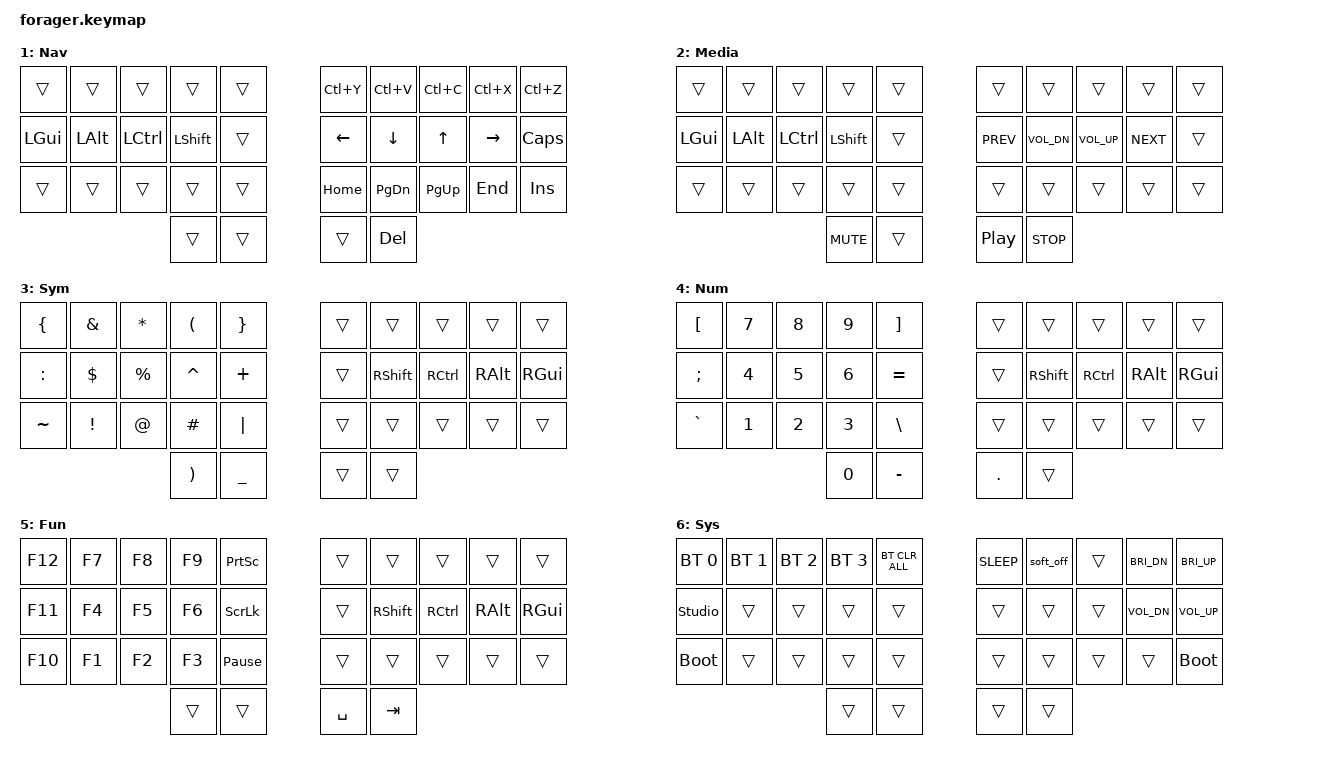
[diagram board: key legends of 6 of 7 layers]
#include <behaviors.dtsi>
#include <dt-bindings/zmk/keys.h>
#include <dt-bindings/zmk/bt.h>
#include <dt-bindings/zmk/outputs.h>

#define BASE 0
#define NAV	1
#define MEDIA	2
#define SYM	3
#define NUM	4
#define FUN	5
#define SYS	6

#define ___ &trans
#define XXX &none

#define AS(keycode) &as LS(keycode) keycode// Autoshift Macro
#define MEH LS(LC(LALT))

&lt {
	// require-prior-idle-ms = <100>;
	tapping-term-ms = <150>;
	quick-tap-ms = <200>;
};

&mt {
	quick-tap-ms = <200>;
};

&sk {
	release-after-ms = <900>;
	quick-release;
};

&sl {
	ignore-modifiers;
};


/ {
	behaviors {
		as: auto_shift {
			compatible = "zmk,behavior-hold-tap";
			#binding-cells = <2>;
			tapping-term-ms = <250>;
			require-prior-idle-ms = <100>;
			flavor = "tap-preferred";
			bindings = <&kp>, <&kp>;
		};
		ht: hold_tap {
			compatible = "zmk,behavior-hold-tap";
			#binding-cells = <2>;
			tapping-term-ms = <200>;
			flavor = "balanced";
			bindings = <&kp>, <&kp>;
		};
		num_layer: tap_dance_mod_tap {
			compatible = "zmk,behavior-tap-dance";
			#binding-cells = <0>;
			tapping-term-ms = <200>;
			bindings = <&lt NUM ENTER>, <&nw>;
		};
		sabk: shift_to_alt_backspace {
			compatible = "zmk,behavior-mod-morph";
			#binding-cells = <0>;
			bindings = <&kp BSPC>, <&kp LA(BSPC)>;
			mods = <(MOD_LSFT|MOD_RSFT)>;
		};
		smart_shift: smart_shift {
			compatible = "zmk,behavior-mod-morph";
			#binding-cells = <0>;
			bindings = <&sk LSHFT>, <&caps_word>;
			mods = <(MOD_LSFT|MOD_RSFT)>;
		};
		sym_bspc: left_thumb_hold_tap {
			compatible = "zmk,behavior-hold-tap";
			#binding-cells = <2>;
			flavor = "tap-preferred";
			tapping-term-ms = <150>;
			quick-tap-ms = <200>;
			bindings = <&mo>, <&sabk>;
		};
		lhm: left_homerow_mods {
			compatible = "zmk,behavior-hold-tap";
			#binding-cells = <2>;
			flavor = "balanced";
			tapping-term-ms = <280>;
			quick-tap-ms = <175>;
			require-prior-idle-ms = <150>;
			bindings = <&kp>, <&kp>;
			hold-trigger-key-positions = <5 6 7 8 9 15 16 17 18 19 25 26 27 28 29 30 31 32 33>;
		};
		rhm: right_homerow_mods {
			compatible = "zmk,behavior-hold-tap";
			#binding-cells = <2>;
			flavor = "balanced";
			tapping-term-ms = <280>;
			quick-tap-ms = <175>;
			require-prior-idle-ms = <150>;
			bindings = <&kp>, <&kp>;
			hold-trigger-key-positions = <0 1 2 3 4 10 11 12 13 14 20 21 22 23 24 30 31 32 33>;
		};
		nw: num_word {
			compatible = "zmk,behavior-caps-word";
			#binding-cells = <0>;
			continue-list = <N0 N1 N2 N3 N4 N5 N6 N7 N8 N9 DOT COMMA FSLH MINUS EQUAL ENTER>;
		};
	};

	#define COMBO(NAME, BINDINGS, KEYPOS, LAYERS, TERM, QUICKTAP) \
	combo_##NAME { \
		timeout-ms = <TERM>; \
		bindings = <BINDINGS>; \
		key-positions = <KEYPOS>; \
		layers = <LAYERS>; \
		require-prior-idle-ms = <QUICKTAP>; \
	};

	#define THUMB_COMBO(NAME, BINDINGS, KEYPOS) \
	combo_##NAME { \
		timeout-ms = <120>; \
		bindings = <BINDINGS>; \
		key-positions = <KEYPOS>; \
		layers = <BASE>; \
		slow-release; \
	};

	combos {
		compatible = "zmk,combos";
		COMBO(enter, &kp ENTER, 16 17, BASE NAV NUM, 80, 50)
		COMBO(bspc, &kp BSPC, 1 2, BASE NAV NUM, 80, 50)
		COMBO(esc, &kp ESC, 0 1, BASE, 80, 50)
		COMBO(tab, &kp TAB, 10 11, BASE, 80, 50)
		COMBO(open_bracket, AS(LBKT), 2 12, BASE, 80, 50)
		COMBO(open_paren, &kp LPAR, 3 13, BASE, 80, 50)
		COMBO(close_paren, &kp RPAR, 6 16, BASE, 80, 50)
		COMBO(close_bracket, AS(RBKT), 7 17, BASE, 80, 50)
		COMBO(pg_up, &kp PG_UP, 5 6, BASE, 80, 50)
		COMBO(pg_dn, &kp PG_DN, 15 16, BASE, 80, 50)
		COMBO(home, &kp HOME, 4 3, BASE, 80, 50)
		COMBO(end, &kp END, 14 13, BASE, 80, 50)
		THUMB_COMBO(fun, &mo FUN, 30 31)
	};

	conditional_layers {
		compatible = "zmk,conditional-layers";
		tri_layer {
			if-layers = <NAV SYM>;
			then-layer = <SYS>;
		};
	};

	#define HRM_L(PINKY,RING,MIDDLE,INDEX) \
	&lhm LGUI PINKY &lhm LALT RING &lhm LCTRL MIDDLE &lhm LSHFT INDEX

	#define HRM_R(INDEX,MIDDLE,RING,PINKY) \
	&rhm RSHFT INDEX &rhm RCTRL MIDDLE &rhm RALT RING &rhm RGUI PINKY

	keymap {
		compatible = "zmk,keymap";

		base {
			label = "Base";
			bindings = <
			&kp Q      	&kp W	&kp E	&kp R 	&kp T	&kp Y	&kp U      	&kp I	&kp O	&kp P
			HRM_L(A,     S,     D,     F)	&kp G	&kp H	    HRM_R(J,     K,     L,     APOS)
			&kp Z	&kp X	&kp C	&kp V	&kp B	&kp N	&kp M	AS(COMMA)	AS(DOT)	AS(FSLH)
			&lt NAV SPACE	&lt MEDIA TAB	&lt SYM ENTER	&lt NUM BSPC
			>;
		};

		nav {
			label = "Nav";
			bindings = <
			___	___	___	___	___	&kp LC(Y)	&kp LC(V)	&kp LC(C)	&kp LC(X)	&kp LC(Z)
			&kp LGUI	&kp LALT	&kp LCTRL	&kp LSHIFT	___	&kp LEFT	&kp DOWN	&kp UP	&kp RIGHT	&kp CAPS
			___	___	___	___	___	&kp HOME	&kp PG_DN	&kp PG_UP	&kp END	&kp INS
			___	___	___	&kp DEL
			>;
		};

		media {
			label = "Media";
			bindings = <
			___	___	___	___	___	___	___	___	___	___
			&kp LGUI	&kp LALT	&kp LCTRL	&kp LSHIFT	___	&kp C_PREV	&kp C_VOL_DN	&kp C_VOL_UP	&kp C_NEXT	___
			___	___	___	___	___	___	___	___	___	___
			&kp C_MUTE	___	&kp C_PP	&kp C_STOP
			>;
		};

		sym {
			label = "Sym";
			bindings = <
			&kp LBRC	&kp AMPS	&kp ASTRK	&kp LPAR	&kp RBRC	___	___	___	___	___
			&kp COLON	&kp DLLR	&kp PRCNT	&kp CARET	&kp PLUS	___	&kp RSHFT	&kp RCTRL	&kp RALT	&kp RGUI
			&kp TILDE	&kp EXCL	&kp AT	&kp HASH	&kp PIPE	___	___	___	___	___
			&kp RPAR	&kp UNDER	___	___
			>;
		};

		num {
			label = "Num";
			bindings = <
			&kp LBKT	&kp N7	&kp N8	&kp N9	&kp RBKT	___	___	___	___	___
			&kp SEMI	&kp N4	&kp N5	&kp N6	&kp EQUAL	___	&kp RSHFT	&kp RCTRL	&kp RALT	&kp RGUI
			&kp GRAVE	&kp N1	&kp N2	&kp N3	&kp BSLH	___	___	___	___	___
			&kp N0	&kp MINUS	&kp DOT	___
			>;
		};

		fun {
			label = "Fun";
			bindings = <
			&kp F12	&kp F7	&kp F8	&kp F9	&kp PSCRN	___	___	___	___	___
			&kp F11	&kp F4	&kp F5	&kp F6	&kp SLCK	___	&kp RSHFT	&kp RCTRL	&kp RALT	&kp RGUI
			&kp F10	&kp F1	&kp F2	&kp F3	&kp PAUSE_BREAK	___	___	___	___	___
			___	___	&kp SPACE	&kp TAB
			>;
		};

		sys {
			label = "Sys";
			bindings = <
			&bt BT_SEL 0	&bt BT_SEL 1	&bt BT_SEL 2	&bt BT_SEL 3	&bt BT_CLR_ALL	&kp C_SLEEP	&soft_off	___	&kp C_BRI_DN	&kp C_BRI_UP
			&studio_unlock	___	___	___	___	___	___	___	&kp C_VOL_DN	&kp C_VOL_UP
			&bootloader	___	___	___	___	___	___	___	___	&bootloader
			___	___	___	___
			>;
		};
	};
};
